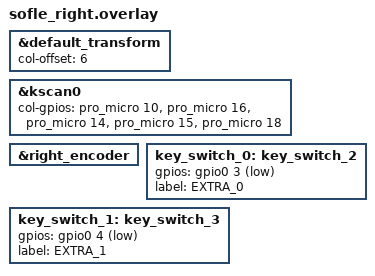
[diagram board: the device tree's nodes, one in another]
/*
 * Copyright (c) 2020 Ryan Cross
 *
 * SPDX-License-Identifier: MIT
 */

#include "sofle.dtsi"

&default_transform {
    col-offset = <6>;
};

&kscan0 {
    col-gpios
        = <&pro_micro 10 GPIO_ACTIVE_HIGH>
        , <&pro_micro 16 GPIO_ACTIVE_HIGH>
        , <&pro_micro 14 GPIO_ACTIVE_HIGH>
        , <&pro_micro 15 GPIO_ACTIVE_HIGH>
        , <&pro_micro 18 GPIO_ACTIVE_HIGH>
        ;
};

&right_encoder {
    status = "okay";
};

 key_switch_0: key_switch_2 {
        gpios = <&gpio0 3 GPIO_ACTIVE_LOW>;
        label = "EXTRA_0";
    };

    key_switch_1: key_switch_3 {
        gpios = <&gpio0 4 GPIO_ACTIVE_LOW>;
        label = "EXTRA_1";
    };
